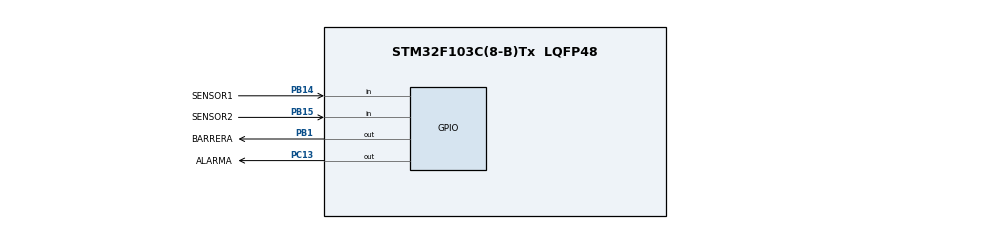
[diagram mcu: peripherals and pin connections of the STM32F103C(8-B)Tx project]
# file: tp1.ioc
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Mcu.Family=STM32F1
PC15-OSC32_OUT.Mode=LSE-External-Oscillator
PD1-OSC_OUT.Mode=HSE-External-Oscillator
PB14.GPIO_Label=SENSOR1
PC13-TAMPER-RTC.Signal=GPIO_Output
PD0-OSC_IN.Signal=RCC_OSC_IN
PC14-OSC32_IN.Signal=RCC_OSC32_IN
PB15.Signal=GPIO_Input
ProjectManager.StackSize=0x400
PD1-OSC_OUT.Signal=RCC_OSC_OUT
PA13.Signal=SYS_JTMS-SWDIO
ProjectManager.TargetToolchain=STM32CubeIDE
PC15-OSC32_OUT.Signal=RCC_OSC32_OUT
PD0-OSC_IN.Mode=HSE-External-Oscillator
PB14.Signal=GPIO_Input
board=custom
PC13-TAMPER-RTC.GPIO_Label=ALARMA
RCC.APB2Freq_Value=8000000
PC14-OSC32_IN.Mode=LSE-External-Oscillator
PC13-TAMPER-RTC.PinState=GPIO_PIN_SET
PB15.GPIO_Label=SENSOR2
PA14.Mode=Serial_Wire
PB1.GPIO_Label=BARRERA
PA13.Mode=Serial_Wire
Mcu.Name=STM32F103C(8-B)Tx
PB1.PinState=GPIO_PIN_SET
Mcu.Package=LQFP48
PB14.GPIO_PuPd=GPIO_PULLUP
PB1.Signal=GPIO_Output
PB15.GPIO_PuPd=GPIO_PULLUP
PA14.Signal=SYS_JTCK-SWCLK
ProjectManager.HeapSize=0x200
NVIC.PriorityGroup=NVIC_PRIORITYGROUP_4
RCC.APB1Freq_Value=8000000

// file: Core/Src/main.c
/* USER CODE BEGIN Header */
/**
  ******************************************************************************
  * @file           : main.c
  * @brief          : Main program body
  ******************************************************************************
  * @attention
  *
  * <h2><center>&copy; Copyright (c) 2021 STMicroelectronics.
  * All rights reserved.</center></h2>
  *
  * This software component is licensed by ST under BSD 3-Clause license,
  * the "License"; You may not use this file except in compliance with the
  * License. You may obtain a copy of the License at:
  *                        opensource.org/licenses/BSD-3-Clause
  *
  ******************************************************************************
  */
/* USER CODE END Header */
#include "main.h"

/* USER CODE BEGIN Includes */
#include "fsm_garaje.h"
#include "user_gpio.h"
/* USER CODE END Includes */

void SystemClock_Config(void);
static void MX_GPIO_Init(void);

/* USER CODE BEGIN 0 */
void HAL_IncTick(void)
{
	fsmGarajeTick();
}

/* USER CODE END 0 */

int main(void)
{

  /* MCU Configuration--------------------------------------------------------*/

  /* Reset of all peripherals, Initializes the Flash interface and the Systick. */
  HAL_Init();

  /* Configure the system clock */
  SystemClock_Config();

  /* Initialize all configured peripherals */
  MX_GPIO_Init();
  /* USER CODE BEGIN 2 */
  user_gpio_init();
  fsmGarajeInit();
  /* USER CODE END 2 */

  /* Infinite loop */
  /* USER CODE BEGIN WHILE */
  while (1)
  {
	  user_gpio();
	  fsmGaraje();

	  __WFI();
    /* USER CODE END WHILE */

  }
}

void SystemClock_Config(void)
{
  RCC_OscInitTypeDef RCC_OscInitStruct = {0};
  RCC_ClkInitTypeDef RCC_ClkInitStruct = {0};

  /** Initializes the RCC Oscillators according to the specified parameters
  * in the RCC_OscInitTypeDef structure.
  */
  RCC_OscInitStruct.OscillatorType = RCC_OSCILLATORTYPE_HSI;
  RCC_OscInitStruct.HSIState = RCC_HSI_ON;
  RCC_OscInitStruct.HSICalibrationValue = RCC_HSICALIBRATION_DEFAULT;
  RCC_OscInitStruct.PLL.PLLState = RCC_PLL_NONE;
  if (HAL_RCC_OscConfig(&RCC_OscInitStruct) != HAL_OK)
  {
    Error_Handler();
  }
  /** Initializes the CPU, AHB and APB buses clocks
  */
  RCC_ClkInitStruct.ClockType = RCC_CLOCKTYPE_HCLK|RCC_CLOCKTYPE_SYSCLK
                              |RCC_CLOCKTYPE_PCLK1|RCC_CLOCKTYPE_PCLK2;
  RCC_ClkInitStruct.SYSCLKSource = RCC_SYSCLKSOURCE_HSI;
  RCC_ClkInitStruct.AHBCLKDivider = RCC_SYSCLK_DIV1;
  RCC_ClkInitStruct.APB1CLKDivider = RCC_HCLK_DIV1;
  RCC_ClkInitStruct.APB2CLKDivider = RCC_HCLK_DIV1;

  if (HAL_RCC_ClockConfig(&RCC_ClkInitStruct, FLASH_LATENCY_0) != HAL_OK)
  {
    Error_Handler();
  }
}

static void MX_GPIO_Init(void)
{
  GPIO_InitTypeDef GPIO_InitStruct = {0};

  /* GPIO Ports Clock Enable */
  __HAL_RCC_GPIOC_CLK_ENABLE();
  __HAL_RCC_GPIOD_CLK_ENABLE();
  __HAL_RCC_GPIOB_CLK_ENABLE();
  __HAL_RCC_GPIOA_CLK_ENABLE();

  /*Configure GPIO pin Output Level */
  HAL_GPIO_WritePin(ALARMA_GPIO_Port, ALARMA_Pin, GPIO_PIN_SET);

  /*Configure GPIO pin Output Level */
  HAL_GPIO_WritePin(BARRERA_GPIO_Port, BARRERA_Pin, GPIO_PIN_SET);

  /*Configure GPIO pin : ALARMA_Pin */
  GPIO_InitStruct.Pin = ALARMA_Pin;
  GPIO_InitStruct.Mode = GPIO_MODE_OUTPUT_PP;
  GPIO_InitStruct.Pull = GPIO_NOPULL;
  GPIO_InitStruct.Speed = GPIO_SPEED_FREQ_LOW;
  HAL_GPIO_Init(ALARMA_GPIO_Port, &GPIO_InitStruct);

  /*Configure GPIO pin : BARRERA_Pin */
  GPIO_InitStruct.Pin = BARRERA_Pin;
  GPIO_InitStruct.Mode = GPIO_MODE_OUTPUT_PP;
  GPIO_InitStruct.Pull = GPIO_NOPULL;
  GPIO_InitStruct.Speed = GPIO_SPEED_FREQ_LOW;
  HAL_GPIO_Init(BARRERA_GPIO_Port, &GPIO_InitStruct);

  /*Configure GPIO pins : SENSOR1_Pin SENSOR2_Pin */
  GPIO_InitStruct.Pin = SENSOR1_Pin|SENSOR2_Pin;
  GPIO_InitStruct.Mode = GPIO_MODE_INPUT;
  GPIO_InitStruct.Pull = GPIO_PULLUP;
  HAL_GPIO_Init(GPIOB, &GPIO_InitStruct);

}

void Error_Handler(void)
{
  __disable_irq();
  while (1)
  {
  }
}

/************************ (C) COPYRIGHT STMicroelectronics *****END OF FILE****/
